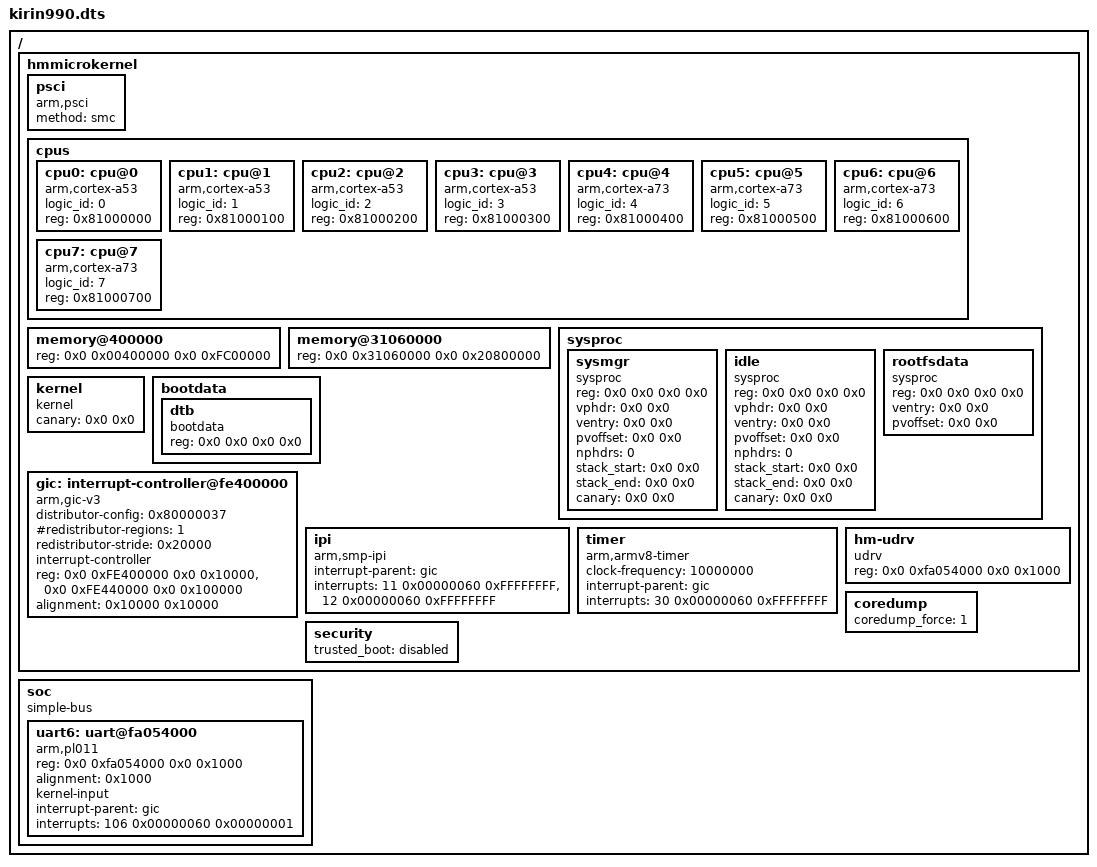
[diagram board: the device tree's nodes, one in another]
/dts-v1/;
/ { #address-cells = <2>; #size-cells = <2>; hmmicrokernel {
	#address-cells = <2>;
	#size-cells = <2>;

	psci {
		compatible = "arm,psci";
		method = "smc";
	};

	cpus {
		#address-cells = <1>;
		#size-cells = <0>;
		cpu0: cpu@0 {
			compatible = "arm,cortex-a53", "arm,armv8";
			device_type = "cpu";
			logic_id = <0>;
			reg = <0x81000000>;
		};
		cpu1: cpu@1 {
			compatible = "arm,cortex-a53", "arm,armv8";
			device_type = "cpu";
			logic_id = <1>;
			reg = <0x81000100>;
		};
		cpu2: cpu@2 {
			compatible = "arm,cortex-a53", "arm,armv8";
			device_type = "cpu";
			logic_id = <2>;
			reg = <0x81000200>;
		};
		cpu3: cpu@3 {
			compatible = "arm,cortex-a53", "arm,armv8";
			device_type = "cpu";
			logic_id = <3>;
			reg = <0x81000300>;
		};
		cpu4: cpu@4 {
			compatible = "arm,cortex-a73", "arm,armv8";
			device_type = "cpu";
			logic_id = <4>;
			reg = <0x81000400>;
		};
		cpu5: cpu@5 {
			compatible = "arm,cortex-a73", "arm,armv8";
			device_type = "cpu";
			logic_id = <5>;
			reg = <0x81000500>;
		};
		cpu6: cpu@6 {
			compatible = "arm,cortex-a73", "arm,armv8";
			device_type = "cpu";
			logic_id = <6>;
			reg = <0x81000600>;
		};
		cpu7: cpu@7 {
			compatible = "arm,cortex-a73", "arm,armv8";
			device_type = "cpu";
			logic_id = <7>;
			reg = <0x81000700>;
		};
	};

	memory@400000 {
		device_type = "memory";
		reg = <0x0 0x00400000 0x0 0xFC00000>;
	};

	memory@31060000 {
		device_type = "memory";
		reg = <0x0 0x31060000 0x0 0x20800000>;
	};

	sysproc {
		#address-cells = <2>;
		#size-cells = <2>;
		sysmgr {
			compatible = "sysproc", "sysmgr";
			/* filled by bootloader */
			reg      = <0x0 0x0 0x0 0x0>;
			vphdr    = <0x0 0x0>;
			ventry   = <0x0 0x0>;
			pvoffset = <0x0 0x0>;
			nphdrs   = <0>;
			stack_start = <0x0 0x0>;
			stack_end = <0x0 0x0>;
			canary = <0x0 0x0>;
		};
		idle {
			compatible = "sysproc", "idle";
			/* filled by bootloader */
			reg      = <0x0 0x0 0x0 0x0>;
			vphdr    = <0x0 0x0>;
			ventry   = <0x0 0x0>;
			pvoffset = <0x0 0x0>;
			nphdrs   = <0>;
			stack_start = <0x0 0x0>;
			stack_end = <0x0 0x0>;
			canary = <0x0 0x0>;
		};
		rootfsdata {
			compatible = "sysproc", "rootfs";
			/* filled by bootloader */
			reg      = <0x0 0x0 0x0 0x0>;
			ventry   = <0x0 0x0>;
			pvoffset = <0x0 0x0>;
		};

	};

	kernel {
		compatible = "kernel";
		/* filled by bootloader */
		canary = <0x0 0x0>;
	};

	bootdata {
		#address-cells = <2>;
		#size-cells = <2>;
		dtb {
			compatible = "bootdata", "dtb";
			/* filled by bootloader */
			reg = <0x0 0x0 0x0 0x0>;
		};
	};

	/* See Documentation/dts-gic.md for interrupts and distributor_config */
	gic: interrupt-controller@fe400000 {
		compatible = "arm,gic-v3";

		#address-cells = <2>;
		#size-cells = <2>;
		distributor-config = <0x80000037>;
		#interrupt-cells = <3>;
		#redistributor-regions = <1>;
		redistributor-stride = <0x20000>;
		interrupt-controller;

		reg =	<0x0 0xFE400000 0x0 0x10000>,   /* GICD */
			<0x0 0xFE440000 0x0 0x100000>;  /* GICR */
		alignment = <0x10000 0x10000>;
	};

	ipi {
		/* smp ipi */
		compatible = "arm,smp-ipi";

		interrupt-parent = <&gic>;

		/* interrupt settings:
		 * 1st cell: real hardware irq number
		 *     ARM recommendation: ID 0-7 for Non-Secure;
		 *                         ID 8-15 for Secure Interrupt
		 * 2nd cell: interrupt config
		 *     bit [27:26]: Group setting
		 *     bit [24]: Trigger Type
		 *     bit [23:8]: Reserved
		 *     bit [7:0]: Priority
		 * 3rd cell: interrupt target config
		 *     Warning: Send all cpus by defult
		 */
		interrupts =	<11 0x00000060 0xFFFFFFFF>, /* IPI_RESCHEDULE */
				<12 0x00000060 0xFFFFFFFF>; /* IPI_CALL_FUNC */
	};

	timer {
		compatible = "arm,armv8-timer";
		clock-frequency = <10000000>;

		/* interrupt settings */
		interrupt-parent = <&gic>;

		/* PPI 30: Non-secure physical timer
		 * level triggered, hwprio:0x60 */
		interrupts = <30 0x00000060 0xFFFFFFFF>;
	};

	hm-udrv {
		compatible = "udrv";
		reg = <0x0 0xfa054000 0x0 0x1000>;
	};

	coredump {
		coredump_force = <1>;
	};
	security {
		trusted_boot = "disabled";
	};
	};

	soc {
		compatible = "simple-bus";
		#address-cells = <2>;
		#size-cells = <2>;
		ranges;

		uart6: uart@fa054000 {
			compatible = "arm,pl011", "arm,pl011,uart";
			reg = <0x0 0xfa054000 0x0 0x1000>;
			alignment = <0x1000>;

			kernel-input;

			interrupt-parent = <&gic>;
			/* secure irq, group setting is 0b11 bit[27:26] */
			interrupts = <106 0x00000060 0x00000001>; /* pl011 uart6 interrupt for receiving */
		};

	};
};
